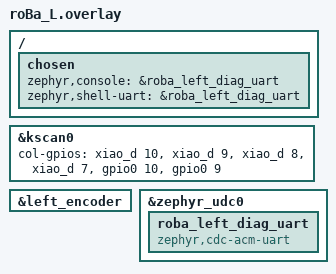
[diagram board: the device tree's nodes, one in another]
#include "roBa.dtsi"

&kscan0 {
        col-gpios
            = <&xiao_d 10 GPIO_ACTIVE_HIGH>
            , <&xiao_d 9 GPIO_ACTIVE_HIGH> 
            , <&xiao_d 8 GPIO_ACTIVE_HIGH> 
            , <&xiao_d 7 GPIO_ACTIVE_HIGH> 
            , <&gpio0 10 GPIO_ACTIVE_HIGH>
            , <&gpio0 9 GPIO_ACTIVE_HIGH>
            ;
};

&left_encoder {
    status = "okay";
};

// Diagnostic only: expose a CDC ACM console on the left half's USB port.
/ {
    chosen {
        zephyr,console = &roba_left_diag_uart;
        zephyr,shell-uart = &roba_left_diag_uart;
    };
};

&zephyr_udc0 {
    roba_left_diag_uart: roba_left_diag_uart {
        compatible = "zephyr,cdc-acm-uart";
    };
};
